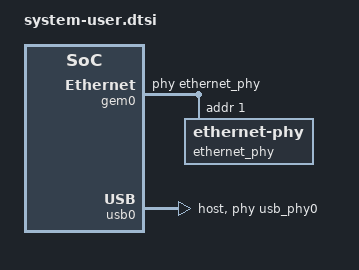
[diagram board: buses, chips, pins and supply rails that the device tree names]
/include/ "system-conf.dtsi"
/ {

	usb_phy0: phy0@e0002000 {
		compatible = "ulpi-phy";
		#phy-cells = <0>;
		reg = <0xe0002000 0x1000>;
		view-port = <0x0170>;
		drv-vbus;
	};
};

&gem0 {
	phy-handle = <&ethernet_phy>;
	ethernet_phy: ethernet-phy@0 { /* rtl8211e-vl */
		reg = <1>;
		device_type = "ethernet-phy";
	};
};

&qspi {
    u-boot,dm-pre-reloc;
};

&flash0 {
        compatible = "jedec,spi-nor";
        reg = <0x0>;
        spi-tx-bus-width = <1>;
        spi-rx-bus-width = <4>;
        spi-max-frequency = <100000000>;
};

&usb0 {
	status = "okay";
	dr_mode = "host";
	usb-phy = <&usb_phy0>;
};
